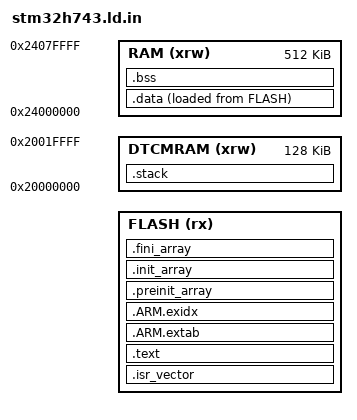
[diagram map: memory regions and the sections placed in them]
/* STM32H743: application in Flash, data in AXI SRAM, stack in DTCM. */
ENTRY(Reset_Handler)

MEMORY
{
  FLASH (rx)    : ORIGIN = @FLASH_ORIGIN@, LENGTH = @FLASH_LENGTH_KB@K
  RAM (xrw)     : ORIGIN = 0x24000000, LENGTH = 512K
  DTCMRAM (xrw) : ORIGIN = 0x20000000, LENGTH = 128K
}

PHDRS
{
  flash PT_LOAD FLAGS(5); /* read, execute */
  ram PT_LOAD FLAGS(6);   /* read, write */
  stack PT_LOAD FLAGS(6);
}

_estack = ORIGIN(DTCMRAM) + LENGTH(DTCMRAM);
_Min_Stack_Size = 16K;

SECTIONS
{
  .isr_vector :
  {
    . = ALIGN(4);
    KEEP(*(.isr_vector))
    . = ALIGN(4);
  } > FLASH :flash

  .text :
  {
    . = ALIGN(4);
    *(.text .text.*)
    *(.rodata .rodata.*)
    *(.glue_7 .glue_7t)
    KEEP(*(.init))
    KEEP(*(.fini))
    . = ALIGN(4);
    _etext = .;
  } > FLASH :flash

  .ARM.extab : { *(.ARM.extab* .gnu.linkonce.armextab.*) } > FLASH :flash
  .ARM.exidx :
  {
    __exidx_start = .;
    *(.ARM.exidx*)
    __exidx_end = .;
  } > FLASH :flash

  .preinit_array :
  {
    PROVIDE_HIDDEN(__preinit_array_start = .);
    KEEP(*(.preinit_array*))
    PROVIDE_HIDDEN(__preinit_array_end = .);
  } > FLASH :flash
  .init_array :
  {
    PROVIDE_HIDDEN(__init_array_start = .);
    KEEP(*(SORT(.init_array.*)))
    KEEP(*(.init_array*))
    PROVIDE_HIDDEN(__init_array_end = .);
  } > FLASH :flash
  .fini_array :
  {
    PROVIDE_HIDDEN(__fini_array_start = .);
    KEEP(*(SORT(.fini_array.*)))
    KEEP(*(.fini_array*))
    PROVIDE_HIDDEN(__fini_array_end = .);
  } > FLASH :flash

  _sidata = LOADADDR(.data);
  .data :
  {
    . = ALIGN(8);
    _sdata = .;
    *(.data .data.*)
    *(.RamFunc .RamFunc.*)
    . = ALIGN(8);
    _edata = .;
  } > RAM AT > FLASH :ram

  .bss (NOLOAD) :
  {
    . = ALIGN(8);
    _sbss = .;
    __bss_start__ = .;
    *(.bss .bss.*)
    *(COMMON)
    . = ALIGN(8);
    _ebss = .;
    __bss_end__ = .;
    end = .;
    _end = .;
  } > RAM :ram

  .stack ORIGIN(DTCMRAM) + LENGTH(DTCMRAM) - _Min_Stack_Size (NOLOAD) :
  {
    . = ALIGN(8);
    __stack_limit = .;
    . += _Min_Stack_Size;
  } > DTCMRAM :stack

  .ARM.attributes 0 : { *(.ARM.attributes) }
  /DISCARD/ : { *(.note.GNU-stack) *(.comment) }
}

ASSERT(_ebss <= ORIGIN(RAM) + LENGTH(RAM), "AXI SRAM overflow")
ASSERT(SIZEOF(.isr_vector) <= 0x800, "Unexpected vector table size")
